AUTOSAR XML (schema 4-3-1)
package /Component
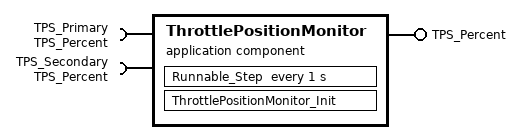
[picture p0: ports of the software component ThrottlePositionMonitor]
  application sw component type ThrottlePositionMonitor
    provide port TPS_Percent: nonqueued-sender-com-spec{data-element=Value_6, init-value=0}, provided-interface=TPS_Percent
    require port TPS_Primary: nonqueued-receiver-com-spec{data-element=Value_6, init-value=0}, required-interface=TPS_Percent
    require port TPS_Secondary: nonqueued-receiver-com-spec{data-element=Value_6, init-value=0}, required-interface=TPS_Percent
    behavior test_IB: handle-termination-and-restart=NO-SUPPORT
      timing event Event_Runnable_Step: start-on-event=Runnable_Step, period=1
      runnable Runnable_Step
        data-read-access:
          access IN_TPS_Secondary_Value_6: accessed-variable=TPS_Secondary.Value_6
          access IN_TPS_Primary_Value_6: accessed-variable=TPS_Primary.Value_6
        data-write-access:
          access OUT_TPS_Percent_Value_6: accessed-variable=TPS_Percent.Value_6
      runnable ThrottlePositionMonitor_Init
